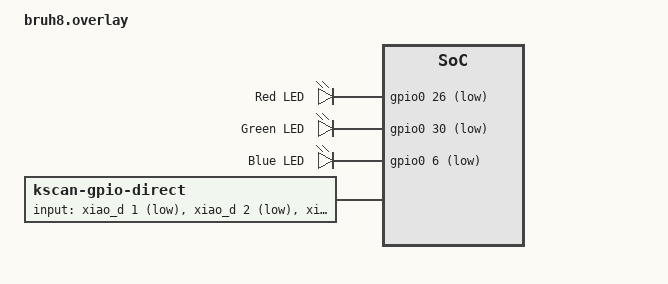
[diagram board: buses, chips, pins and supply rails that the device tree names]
&gpio0 {
	status = "okay";
};

/ {
  chosen {
    zmk,kscan = &kscan0;
    zmk,backlight = &backlight;
  };

  backlight: gpioleds {
    compatible = "gpio-leds";
    label = "Onboard LEDs";
    led_0 {
      gpios = <&gpio0 26 GPIO_ACTIVE_LOW>;
      label = "Red LED";
    };
    led_1 {
      gpios = <&gpio0 30 GPIO_ACTIVE_LOW>;
      label = "Green LED";
    };
    led_2 {
      gpios = <&gpio0 6 GPIO_ACTIVE_LOW>;
      label = "Blue LED";
    };
  };

  kscan0: kscan_0 {
    compatible = "zmk,kscan-gpio-direct";
    label = "KSCAN";
    input-gpios
      = <&xiao_d 1 (GPIO_ACTIVE_LOW | GPIO_PULL_UP)>
      , <&xiao_d 2 (GPIO_ACTIVE_LOW | GPIO_PULL_UP)>
      , <&xiao_d 3 (GPIO_ACTIVE_LOW | GPIO_PULL_UP)>
      , <&xiao_d 6 (GPIO_ACTIVE_LOW | GPIO_PULL_UP)>
      , <&xiao_d 10 (GPIO_ACTIVE_LOW | GPIO_PULL_UP)>
      , <&xiao_d 9 (GPIO_ACTIVE_LOW | GPIO_PULL_UP)>
      , <&xiao_d 8 (GPIO_ACTIVE_LOW | GPIO_PULL_UP)>
      , <&xiao_d 7 (GPIO_ACTIVE_LOW | GPIO_PULL_UP)>
      ;
  };
};
